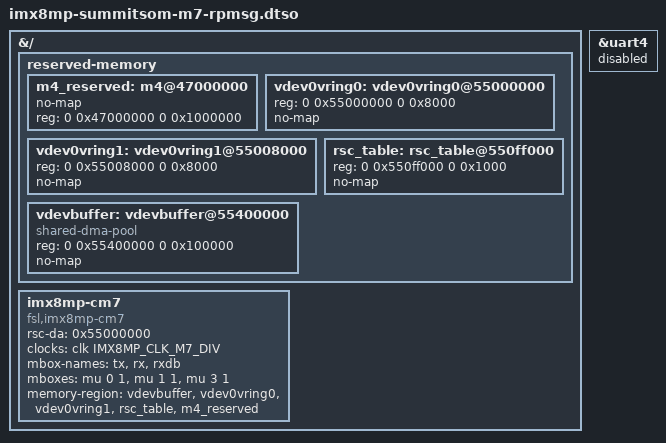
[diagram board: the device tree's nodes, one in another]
// SPDX-License-Identifier: LicenseRef-Ezurio-Clause
/*
 * Copyright 2022 Ezurio
 */

/dts-v1/;
/plugin/;

#include <dt-bindings/clock/imx8mp-clock.h>

&{/} {
	reserved-memory {
		#address-cells = <2>;
		#size-cells = <2>;

		m4_reserved: m4@47000000 {
			no-map;
			reg = <0 0x47000000 0 0x1000000>;
		};

		vdev0vring0: vdev0vring0@55000000 {
			reg = <0 0x55000000 0 0x8000>;
			no-map;
		};

		vdev0vring1: vdev0vring1@55008000 {
			reg = <0 0x55008000 0 0x8000>;
			no-map;
		};

		rsc_table: rsc_table@550ff000 {
			reg = <0 0x550ff000 0 0x1000>;
			no-map;
		};

		vdevbuffer: vdevbuffer@55400000 {
			compatible = "shared-dma-pool";
			reg = <0 0x55400000 0 0x100000>;
			no-map;
		};
/*
		audio_reserved: audio@48000000 {
			compatible = "shared-dma-pool";
			no-map;
			reg = <0 0x48000000 0 0x8000000>;
		};
*/
	};

	imx8mp-cm7 {
		compatible = "fsl,imx8mp-cm7";
		rsc-da = <0x55000000>;
		clocks = <&clk IMX8MP_CLK_M7_DIV>;
		mbox-names = "tx", "rx", "rxdb";
		mboxes = <&mu 0 1
			  &mu 1 1
			  &mu 3 1>;
		memory-region = <&vdevbuffer>, <&vdev0vring0>, <&vdev0vring1>,
			<&rsc_table>, <&m4_reserved>;
	};
};

/*
 * ATTENTION: M7 may use IPs like below
 * ECSPI0/ECSPI2, FLEXCAN, GPIO1/GPIO5, GPT1, I2C3, I2S3, UART4,
 * PWM4, SDMA1/SDMA2
 */

&uart4 {
	status = "disabled";
};
